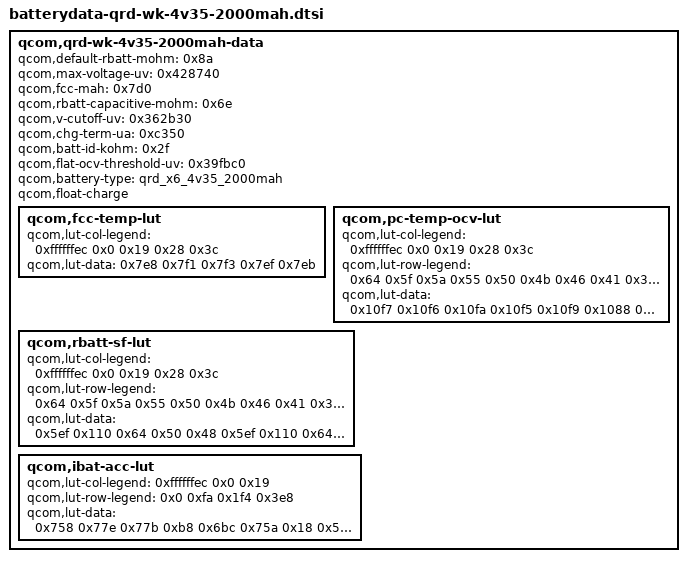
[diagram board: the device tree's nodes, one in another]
/* Copyright (c) 2014, The Linux Foundation. All rights reserved.
 *
 * This program is free software; you can redistribute it and/or modify
 * it under the terms of the GNU General Public License version 2 and
 * only version 2 as published by the Free Software Foundation.
 *
 * This program is distributed in the hope that it will be useful,
 * but WITHOUT ANY WARRANTY; without even the implied warranty of
 * MERCHANTABILITY or FITNESS FOR A PARTICULAR PURPOSE.  See the
 * GNU General Public License for more details.
 */

qcom,qrd-wk-4v35-2000mah-data {
	qcom,default-rbatt-mohm = <0x8a>;
		qcom,max-voltage-uv = <0x428740>;
		qcom,fcc-mah = <0x7d0>;
		qcom,rbatt-capacitive-mohm = <0x6e>;
		qcom,v-cutoff-uv = <0x362b30>;
		qcom,chg-term-ua = <0xc350>;
		qcom,batt-id-kohm = <0x2f>;
		qcom,flat-ocv-threshold-uv = <0x39fbc0>;
		qcom,battery-type = "qrd_x6_4v35_2000mah";
		qcom,float-charge;

	qcom,fcc-temp-lut {
		qcom,lut-col-legend = <0xffffffec 0x0 0x19 0x28 0x3c>;
		qcom,lut-data = <0x7e8 0x7f1 0x7f3 0x7ef 0x7eb>;
			};

			qcom,pc-temp-ocv-lut {
				qcom,lut-col-legend = <0xffffffec 0x0 0x19 0x28 0x3c>;
				qcom,lut-row-legend = <0x64 0x5f 0x5a 0x55 0x50 0x4b 0x46 0x41 0x3c 0x37 0x32 0x2d 0x28 0x23 0x1e 0x19 0x14 0x10 0xd 0xb 0xa 0x9 0x8 0x7 0x6 0x5 0x4 0x3 0x2 0x1 0x0>;
				qcom,lut-data = <0x10f7 0x10f6 0x10fa 0x10f5 0x10f9 0x1088 0x109b 0x109c 0x1098 0x1096 0x1044 0x1060 0x1061 0x105e 0x105c 0x100e 0x102a 0x102a 0x1027 0x1025 0xfe1 0xffa 0xff7 0xff4 0xff2 0xf7e 0xfbc 0xfc6 0xfc4 0xfc2 0xf52 0xf74 0xf90 0xf97 0xf96 0xf2c 0xf55 0xf6f 0xf70 0xf6f 0xf0a 0xf33 0xf41 0xf44 0xf45 0xef0 0xf12 0xf18 0xf19 0xf19 0xedc 0xef6 0xefc 0xefc 0xefc 0xeca 0xedf 0xee6 0xee6 0xee5 0xebc 0xecc 0xed4 0xed4 0xed3 0xead 0xebe 0xec5 0xec6 0xec4 0xea0 0xeb3 0xeb8 0xeb4 0xeae 0xe90 0xea6 0xeaa 0xea0 0xe94 0xe7e 0xe92 0xe98 0xe8f 0xe81 0xe6b 0xe86 0xe86 0xe7c 0xe6e 0xe58 0xe7e 0xe74 0xe6a 0xe5e 0xe46 0xe78 0xe6a 0xe62 0xe56 0xe3d 0xe74 0xe68 0xe60 0xe54 0xe32 0xe6f 0xe67 0xe5f 0xe53 0xe26 0xe69 0xe64 0xe5c 0xe51 0xe14 0xe60 0xe5f 0xe58 0xe4b 0xe00 0xe4f 0xe52 0xe4a 0xe39 0xde6 0xe33 0xe32 0xe27 0xe18 0xdc4 0xe0b 0xe02 0xdf8 0xdea 0xd96 0xdd4 0xdc6 0xdbe 0xdb0 0xd50 0xd85 0xd76 0xd70 0xd60 0xcd4 0xd08 0xd03 0xcf8 0xce6 0xbb8 0xbb8 0xbdc 0xbc4 0xbb8>;
			};

			qcom,rbatt-sf-lut {
				qcom,lut-col-legend = <0xffffffec 0x0 0x19 0x28 0x3c>;
				qcom,lut-row-legend = <0x64 0x5f 0x5a 0x55 0x50 0x4b 0x46 0x41 0x3c 0x37 0x32 0x2d 0x28 0x23 0x1e 0x19 0x14 0x10 0xd 0xb 0xa 0x9 0x8 0x7 0x6 0x5 0x4 0x3 0x2 0x1 0x0>;
				qcom,lut-data = <0x5ef 0x110 0x64 0x50 0x48 0x5ef 0x110 0x64 0x50 0x48 0x596 0x114 0x65 0x51 0x49 0x55c 0x117 0x68 0x53 0x4b 0x547 0x118 0x6c 0x56 0x4c 0x4de 0x122 0x72 0x5a 0x4e 0x4e2 0x10d 0x79 0x5f 0x51 0x4e9 0x10f 0x80 0x65 0x54 0x4f7 0x10d 0x74 0x63 0x56 0x511 0x10e 0x66 0x56 0x4c 0x536 0x112 0x64 0x53 0x49 0x561 0x119 0x67 0x53 0x4b 0x592 0x123 0x6a 0x56 0x4e 0x5c9 0x130 0x6e 0x5b 0x52 0x60f 0x142 0x70 0x58 0x4d 0x666 0x15a 0x6d 0x55 0x4a 0x6dd 0x177 0x70 0x56 0x4b 0x7f4 0x1a8 0x72 0x58 0x4d 0x984 0x1ed 0x71 0x58 0x4c 0xad1 0x225 0x74 0x58 0x4d 0xb63 0x23f 0x76 0x5b 0x50 0xb1d 0x234 0x78 0x5c 0x51 0xc86 0x254 0x7b 0x5e 0x53 0xe5e 0x27f 0x81 0x61 0x56 0x10d5 0x2b5 0x83 0x60 0x52 0x141c 0x2fb 0x81 0x5b 0x50 0x18bf 0x364 0x88 0x5f 0x51 0x1fb4 0x404 0x93 0x64 0x56 0x2adc 0x4f7 0xa7 0x71 0x5c 0x4a37 0x891 0xd5 0x84 0x6b 0x946d 0x1122 0x1aa 0x108 0xd5>;
			};

			qcom,ibat-acc-lut {
				qcom,lut-col-legend = <0xffffffec 0x0 0x19>;
				qcom,lut-row-legend = <0x0 0xfa 0x1f4 0x3e8>;
				qcom,lut-data = <0x758 0x77e 0x77b 0xb8 0x6bc 0x75a 0x18 0x536 0x73c 0x6 0x300 0x683>;
	};
};
